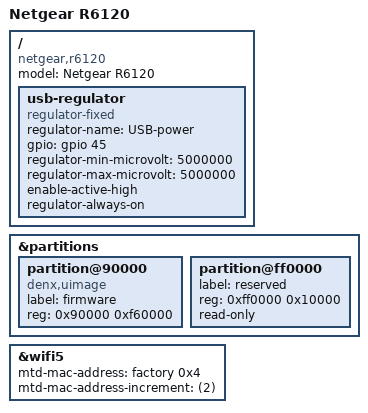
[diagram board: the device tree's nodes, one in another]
#include "mt7628an_netgear_r6xxx.dtsi"

/ {
	compatible = "netgear,r6120", "mediatek,mt7628an-soc";
	model = "Netgear R6120";

	usb-regulator {
		compatible = "regulator-fixed";

		regulator-name = "USB-power";
		gpio = <&gpio 45 GPIO_ACTIVE_HIGH>;
		regulator-min-microvolt = <5000000>;
		regulator-max-microvolt = <5000000>;
		enable-active-high;

		regulator-always-on;
	};
};

&partitions {
	partition@90000 {
		compatible = "denx,uimage";
		label = "firmware";
		reg = <0x90000 0xf60000>;
	};

	partition@ff0000 {
		label = "reserved";
		reg = <0xff0000 0x10000>;
		read-only;
	};
};

&wifi5 {
	mtd-mac-address = <&factory 0x4>;
	mtd-mac-address-increment = <(2)>;
};
